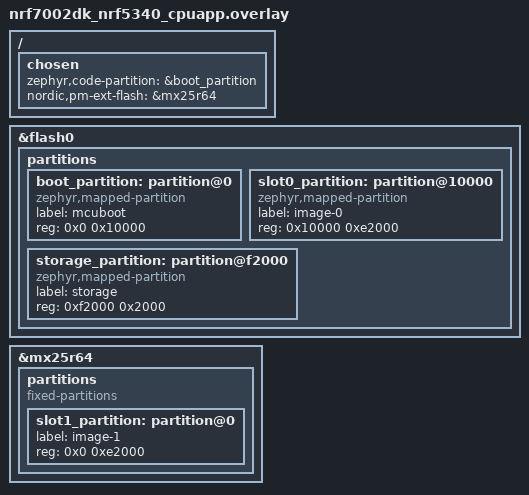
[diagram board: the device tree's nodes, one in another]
/*
 * Copyright (c) 2023 Nordic Semiconductor ASA
 *
 * SPDX-License-Identifier: LicenseRef-Nordic-5-Clause
 */

/ {
	/* Configure partition manager to use mx25r64 as the external flash */
	chosen {
		zephyr,code-partition = &boot_partition;
		nordic,pm-ext-flash = &mx25r64;
	};
};

/delete-node/ &boot_partition;
/delete-node/ &slot0_partition;
/delete-node/ &slot1_partition;
/delete-node/ &storage_partition;

&flash0 {
	partitions {
		boot_partition: partition@0 {
			compatible = "zephyr,mapped-partition";
			label = "mcuboot";
			reg = <0x0 0x10000>;
		};

		/* Must match the application image static partition layout in devicetree. */
		slot0_partition: partition@10000 {
			compatible = "zephyr,mapped-partition";
			label = "image-0";
			reg = <0x10000 0xe2000>;
		};

		storage_partition: partition@f2000 {
			compatible = "zephyr,mapped-partition";
			label = "storage";
			reg = <0xf2000 0x2000>;
		};
	};
};

&mx25r64 {
	status = "okay";

	partitions {
		compatible = "fixed-partitions";
		#address-cells = <1>;
		#size-cells = <1>;

		slot1_partition: partition@0 {
			label = "image-1";
			reg = <0x0 0xe2000>;
		};
	};
};
